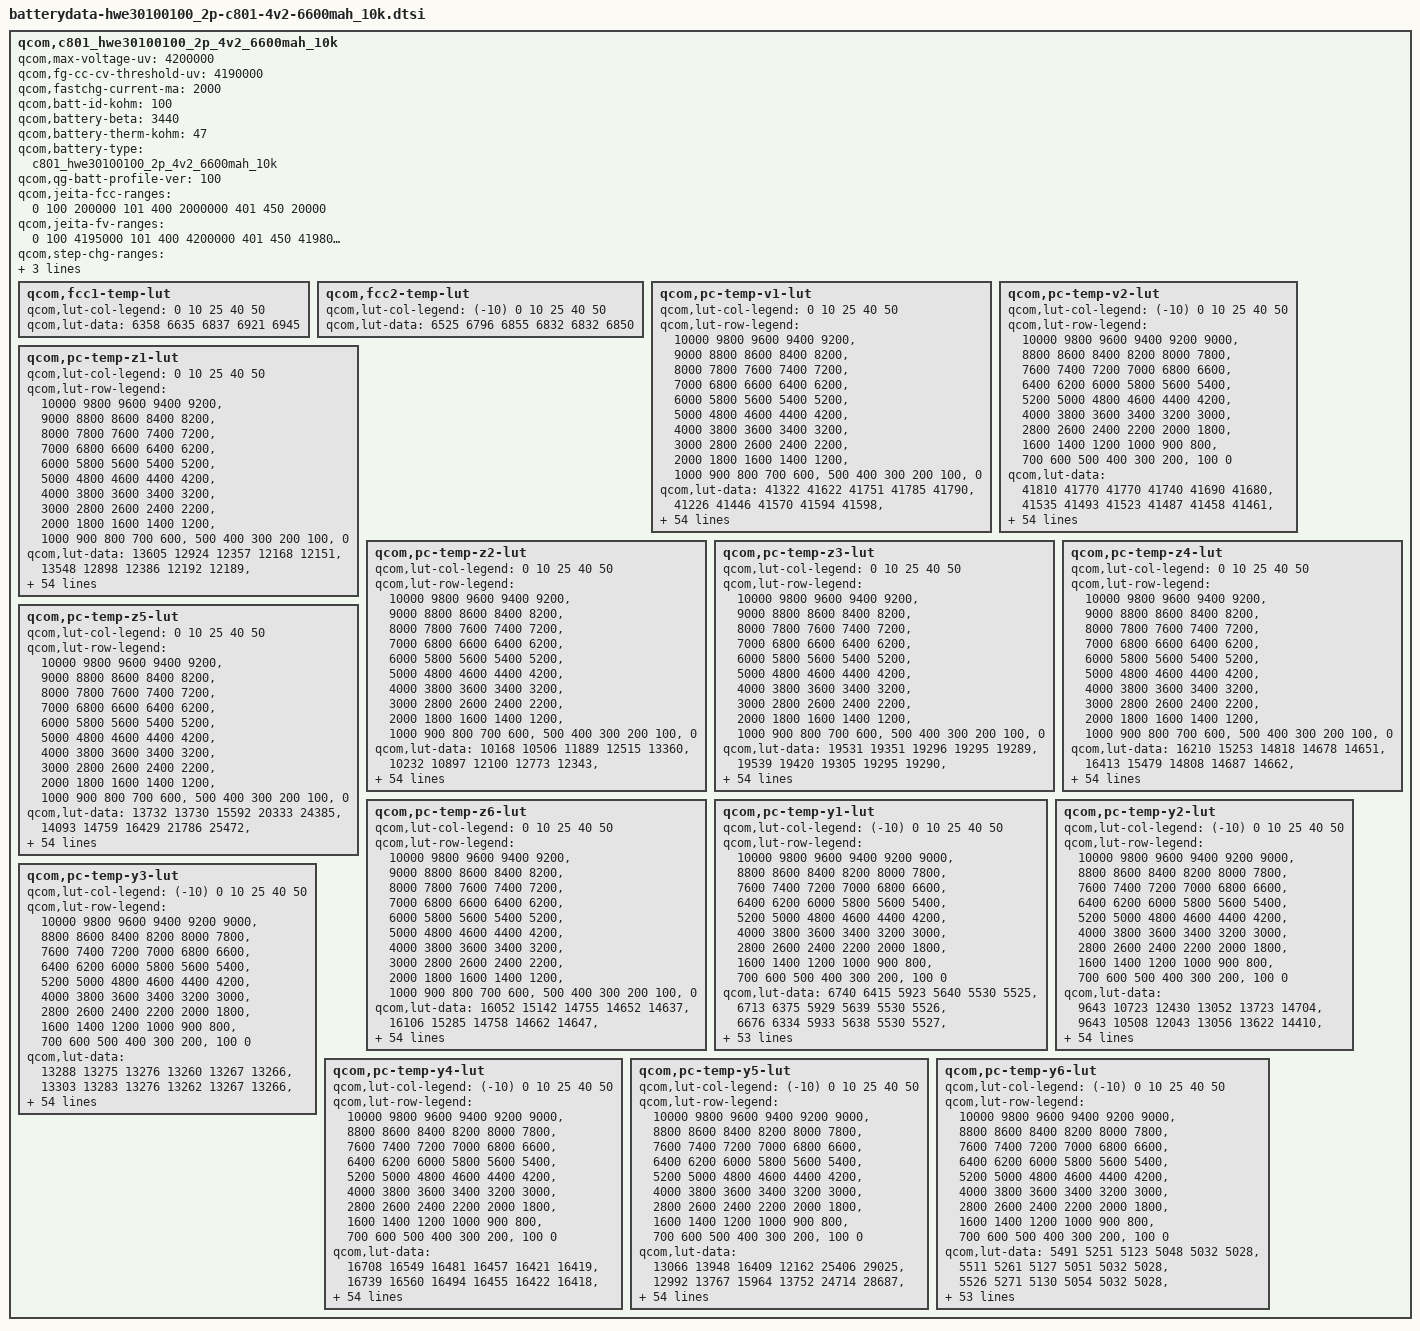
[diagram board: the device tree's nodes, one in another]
/* Copyright (c) 2018, The Linux Foundation. All rights reserved.
 *
 * This program is free software; you can redistribute it and/or modify
 * it under the terms of the GNU General Public License version 2 and
 * only version 2 as published by the Free Software Foundation.
 *
 * This program is distributed in the hope that it will be useful,
 * but WITHOUT ANY WARRANTY; without even the implied warranty of
 * MERCHANTABILITY or FITNESS FOR A PARTICULAR PURPOSE.  See the
 * GNU General Public License for more details.
 */

qcom,c801_hwe30100100_2p_4v2_6600mah_10k {
	/* 5174868_Quectel_SC60-R06_6600mAH_PMI632_averaged_MasterSlave_Apr15th2021*/
	qcom,max-voltage-uv = <4200000>;
	qcom,fg-cc-cv-threshold-uv = <4190000>;
	qcom,fastchg-current-ma = <2000>;
	/*qcom,batt-id-kohm = <10>;*/
	/*qcom,battery-beta = <3435>;*/
	/*qcom,battery-therm-kohm = <10>;*/
	qcom,batt-id-kohm = <100>; /* temporary for investigation */
	qcom,battery-beta = <3440>;
	qcom,battery-therm-kohm = <47>;
	qcom,battery-type = "c801_hwe30100100_2p_4v2_6600mah_10k";
	qcom,qg-batt-profile-ver = <100>;

	qcom,jeita-fcc-ranges = <0   100  200000
				101  400  2000000
				401  450  20000>;
	qcom,jeita-fv-ranges = <0   100  4195000
				101 400  4200000
				401 450  4198000>;
	qcom,step-chg-ranges = <3600000  4190000  2000000
				4191000  4195000  500000
				4196000  4200000  100000>;

	/* COOL = 5 DegC, WARM = 40 DegC */
	qcom,jeita-soft-thresholds = <0x5b70 0x3252>;
	/* COOL = 0 DegC, WARM = 45 DegC */
	/*qcom,jeita-soft-thresholds = <0x3730 0x0FB0>;*/
	/* COLD = 0 DegC, HOT = 45 DegC */
	qcom,jeita-hard-thresholds = <0x5fc9 0x2c99>;
	/* COLD = -10 DegC, HOT = 50 DegC */
	/*qcom,jeita-hard-thresholds = <0x448E 0x0D8F>;*/

	qcom,fcc1-temp-lut {
		qcom,lut-col-legend = <0 10 25 40 50>;
		qcom,lut-data = <6358 6635 6837 6921 6945>;
	};

	qcom,fcc2-temp-lut {
		qcom,lut-col-legend = <(-10) 0 10 25 40 50>;
		qcom,lut-data = <6525 6796 6855 6832 6832 6850>;
	};

	qcom,pc-temp-v1-lut {
		qcom,lut-col-legend = <0 10 25 40 50>;
		qcom,lut-row-legend = <10000 9800 9600 9400 9200>,
			<9000 8800 8600 8400 8200>,
			<8000 7800 7600 7400 7200>,
			<7000 6800 6600 6400 6200>,
			<6000 5800 5600 5400 5200>,
			<5000 4800 4600 4400 4200>,
			<4000 3800 3600 3400 3200>,
			<3000 2800 2600 2400 2200>,
			<2000 1800 1600 1400 1200>,
			<1000 900 800 700 600>,
			<500 400 300 200 100>,
			<0>;
		qcom,lut-data = <41322 41622 41751 41785 41790>,
			<41226 41446 41570 41594 41598>,
			<41016 41261 41378 41408 41408>,
			<40752 41081 41195 41227 41226>,
			<40483 40913 41019 41038 41040>,
			<40187 40736 40861 40864 40862>,
			<39956 40510 40711 40714 40697>,
			<39802 40239 40528 40562 40539>,
			<39680 40042 40287 40381 40379>,
			<39571 39919 40083 40190 40221>,
			<39478 39820 39960 40037 40070>,
			<39385 39723 39860 39913 39926>,
			<39274 39635 39748 39791 39789>,
			<39158 39542 39632 39659 39655>,
			<39044 39436 39515 39530 39528>,
			<38933 39331 39399 39409 39406>,
			<38829 39232 39287 39294 39290>,
			<38733 39138 39180 39183 39176>,
			<38646 39048 39078 39083 39071>,
			<38563 38960 38980 38968 38956>,
			<38476 38874 38892 38789 38792>,
			<38399 38791 38790 38592 38603>,
			<38348 38711 38628 38470 38472>,
			<38315 38638 38444 38387 38377>,
			<38278 38573 38329 38312 38295>,
			<38203 38510 38252 38239 38220>,
			<38108 38438 38192 38173 38153>,
			<38046 38363 38147 38114 38090>,
			<38012 38296 38108 38060 38033>,
			<37979 38237 38068 38012 37982>,
			<37924 38181 38029 37968 37936>,
			<37850 38123 37997 37931 37897>,
			<37785 38068 37970 37901 37867>,
			<37721 38025 37945 37873 37840>,
			<37675 37995 37923 37848 37807>,
			<37694 37967 37901 37823 37769>,
			<37809 37941 37873 37789 37725>,
			<37885 37915 37838 37744 37675>,
			<37882 37881 37791 37684 37614>,
			<37875 37831 37717 37608 37537>,
			<37855 37764 37618 37512 37440>,
			<37769 37660 37505 37400 37328>,
			<37659 37525 37374 37266 37195>,
			<37527 37382 37243 37132 37062>,
			<37392 37256 37130 37015 36948>,
			<37266 37157 37051 36944 36880>,
			<37211 37121 37021 36920 36854>,
			<37165 37089 36998 36900 36834>,
			<37122 37056 36972 36876 36808>,
			<37058 36988 36892 36774 36692>,
			<36899 36719 36604 36474 36383>,
			<36477 36287 36169 36033 35941>,
			<35929 35710 35601 35461 35370>,
			<35184 34930 34824 34684 34594>,
			<34022 33733 33637 33502 33417>,
			<30000 30000 30000 30000 30000>;
	};

	qcom,pc-temp-v2-lut {
		qcom,lut-col-legend = <(-10) 0 10 25 40 50>;
		qcom,lut-row-legend = <10000 9800 9600 9400 9200 9000>,
			<8800 8600 8400 8200 8000 7800>,
			<7600 7400 7200 7000 6800 6600>,
			<6400 6200 6000 5800 5600 5400>,
			<5200 5000 4800 4600 4400 4200>,
			<4000 3800 3600 3400 3200 3000>,
			<2800 2600 2400 2200 2000 1800>,
			<1600 1400 1200 1000 900 800>,
			<700 600 500 400 300 200>,
			<100 0>;
		qcom,lut-data = <41810 41770 41770 41740 41690 41680>,
			<41535 41493 41523 41487 41458 41461>,
			<41297 41259 41304 41262 41242 41253>,
			<41107 41087 41122 41073 41046 41058>,
			<40966 40960 40971 40914 40867 40874>,
			<40804 40800 40800 40744 40691 40698>,
			<40544 40535 40589 40547 40518 40529>,
			<40231 40242 40366 40346 40347 40365>,
			<39966 40006 40144 40152 40181 40205>,
			<39731 39794 39925 39963 40020 40050>,
			<39540 39633 39774 39821 39873 39900>,
			<39410 39517 39677 39720 39743 39758>,
			<39307 39410 39577 39622 39617 39621>,
			<39203 39290 39441 39504 39490 39489>,
			<39099 39166 39288 39377 39366 39363>,
			<38991 39040 39137 39255 39245 39242>,
			<38867 38909 38985 39138 39133 39131>,
			<38732 38783 38842 39006 39007 39007>,
			<38604 38666 38710 38834 38847 38857>,
			<38482 38556 38588 38656 38678 38700>,
			<38365 38448 38477 38514 38531 38548>,
			<38256 38344 38377 38392 38394 38400>,
			<38151 38247 38287 38291 38285 38286>,
			<38054 38159 38209 38208 38201 38202>,
			<37958 38077 38137 38137 38129 38129>,
			<37873 38005 38067 38070 38063 38060>,
			<37802 37939 38003 38011 38003 37998>,
			<37740 37877 37940 37955 37948 37940>,
			<37686 37817 37880 37903 37896 37888>,
			<37639 37762 37825 37855 37849 37841>,
			<37597 37720 37778 37809 37808 37799>,
			<37557 37683 37735 37767 37768 37759>,
			<37519 37638 37698 37728 37726 37717>,
			<37481 37581 37666 37693 37683 37674>,
			<37442 37523 37627 37654 37633 37617>,
			<37402 37461 37578 37607 37570 37530>,
			<37359 37399 37525 37556 37502 37440>,
			<37315 37346 37475 37502 37436 37366>,
			<37266 37299 37420 37443 37369 37297>,
			<37212 37256 37343 37375 37298 37229>,
			<37152 37218 37235 37290 37225 37162>,
			<37084 37181 37145 37201 37137 37075>,
			<37005 37145 37074 37104 37027 36963>,
			<36899 37097 37024 36962 36898 36834>,
			<36757 37019 36987 36891 36806 36747>,
			<36576 36922 36930 36858 36779 36719>,
			<36435 36851 36902 36835 36761 36700>,
			<36308 36744 36857 36814 36735 36674>,
			<36132 36606 36759 36761 36687 36620>,
			<35922 36410 36570 36613 36535 36453>,
			<35674 36073 36272 36263 36180 36096>,
			<35333 35721 35856 35772 35694 35610>,
			<34893 35232 35255 35140 35064 34973>,
			<34242 34541 34387 34276 34200 34109>,
			<33157 33411 33038 33058 33018 32927>,
			<30499 31323 30117 30069 30029 30027>;
	};

	qcom,pc-temp-z1-lut {
		qcom,lut-col-legend = <0 10 25 40 50>;
		qcom,lut-row-legend = <10000 9800 9600 9400 9200>,
			<9000 8800 8600 8400 8200>,
			<8000 7800 7600 7400 7200>,
			<7000 6800 6600 6400 6200>,
			<6000 5800 5600 5400 5200>,
			<5000 4800 4600 4400 4200>,
			<4000 3800 3600 3400 3200>,
			<3000 2800 2600 2400 2200>,
			<2000 1800 1600 1400 1200>,
			<1000 900 800 700 600>,
			<500 400 300 200 100>,
			<0>;
		qcom,lut-data = <13605 12924 12357 12168 12151>,
			<13548 12898 12386 12192 12189>,
			<13478 12928 12394 12205 12201>,
			<13423 12941 12405 12211 12206>,
			<13406 12939 12412 12215 12210>,
			<13398 12937 12411 12213 12210>,
			<13392 12940 12408 12181 12181>,
			<13388 12949 12398 12153 12148>,
			<13385 12952 12358 12157 12151>,
			<13377 12918 12331 12168 12168>,
			<13358 12882 12337 12188 12191>,
			<13337 12880 12352 12228 12229>,
			<13320 12883 12376 12249 12252>,
			<13303 12884 12419 12249 12251>,
			<13279 12877 12439 12250 12250>,
			<13240 12871 12440 12250 12251>,
			<13192 12875 12440 12251 12253>,
			<13138 12888 12442 12253 12255>,
			<13077 12899 12444 12254 12256>,
			<13026 12906 12446 12257 12258>,
			<12985 12914 12447 12259 12260>,
			<12952 12943 12448 12261 12262>,
			<12931 12993 12451 12264 12264>,
			<12917 13022 12454 12266 12265>,
			<12905 13036 12458 12268 12267>,
			<12891 13043 12463 12269 12268>,
			<12878 13043 12468 12271 12269>,
			<12875 13042 12472 12272 12270>,
			<12885 13042 12475 12273 12271>,
			<12900 13044 12477 12274 12271>,
			<12921 13048 12478 12274 12272>,
			<12952 13058 12480 12275 12273>,
			<12983 13074 12483 12276 12275>,
			<13009 13085 12486 12277 12276>,
			<13039 13094 12490 12278 12277>,
			<13086 13099 12494 12279 12278>,
			<13161 13095 12498 12281 12279>,
			<13249 13088 12503 12283 12280>,
			<13354 13087 12507 12285 12281>,
			<13467 13089 12508 12286 12282>,
			<13552 13093 12509 12287 12284>,
			<13622 13097 12512 12288 12284>,
			<13636 13103 12516 12291 12284>,
			<13576 13121 12518 12292 12285>,
			<13575 13119 12520 12293 12286>,
			<13636 13109 12521 12296 12289>,
			<13698 13121 12530 12298 12289>,
			<13719 13112 12526 12298 12289>,
			<13671 13135 12527 12300 12292>,
			<13681 13108 12539 12302 12294>,
			<13675 13143 12540 12307 12297>,
			<13685 13124 12553 12313 12303>,
			<13688 13160 12569 12322 12311>,
			<13728 13147 12583 12334 12321>,
			<13728 13147 12583 12334 12321>,
			<13728 13147 12583 12334 12321>;
	};

	qcom,pc-temp-z2-lut {
		qcom,lut-col-legend = <0 10 25 40 50>;
		qcom,lut-row-legend = <10000 9800 9600 9400 9200>,
			<9000 8800 8600 8400 8200>,
			<8000 7800 7600 7400 7200>,
			<7000 6800 6600 6400 6200>,
			<6000 5800 5600 5400 5200>,
			<5000 4800 4600 4400 4200>,
			<4000 3800 3600 3400 3200>,
			<3000 2800 2600 2400 2200>,
			<2000 1800 1600 1400 1200>,
			<1000 900 800 700 600>,
			<500 400 300 200 100>,
			<0>;
		qcom,lut-data = <10168 10506 11889 12515 13360>,
			<10232 10897 12100 12773 12343>,
			<10403 11124 12118 12938 12587>,
			<10551 11200 12131 12758 12862>,
			<10548 11207 12135 12726 12608>,
			<10484 11213 12113 12696 12468>,
			<10392 11228 12064 12659 12532>,
			<10170 11252 12052 12627 12610>,
			<9927 11272 12058 12599 12626>,
			<9888 11290 12063 12577 12633>,
			<9916 11301 12007 12592 12633>,
			<9940 11286 11923 12689 12615>,
			<9948 11242 11927 12753 12602>,
			<9954 11226 11998 12768 12638>,
			<9953 11249 12056 12775 12692>,
			<9932 11273 12085 12766 12688>,
			<9902 11245 12111 12733 12650>,
			<9875 11167 12149 12699 12634>,
			<9846 11133 12194 12661 12634>,
			<9834 11127 12243 12617 12634>,
			<9852 11124 12307 12565 12609>,
			<9887 11121 12344 12504 12536>,
			<9925 11120 12241 12422 12418>,
			<9975 11093 12067 12314 12192>,
			<10042 10800 12075 12209 12082>,
			<10126 10533 12261 12094 12096>,
			<10261 10731 12360 12019 12120>,
			<11450 11224 12309 12049 12141>,
			<21308 11455 12229 12126 12165>,
			<30541 11522 12168 12172 12200>,
			<26963 11575 12112 12192 12263>,
			<15450 11642 12096 12224 12344>,
			<10012 11708 12112 12371 12451>,
			<9893 11766 12143 12551 12572>,
			<9834 11825 12249 12616 12675>,
			<9827 11858 12432 12653 12773>,
			<9827 11669 12541 12656 12802>,
			<9826 11301 12605 12579 12773>,
			<9754 11216 12663 12514 12746>,
			<9628 11330 12738 12547 12779>,
			<9593 11513 12796 12612 12844>,
			<9593 11907 12780 12634 12833>,
			<9596 12283 12718 12641 12719>,
			<9616 12320 12704 12681 12665>,
			<9465 12112 12719 12766 12659>,
			<9446 11940 13048 12811 12903>,
			<9456 11975 13113 12844 12904>,
			<9434 11819 13335 13055 12871>,
			<9439 12044 13368 13152 12966>,
			<9465 11874 13234 13076 12729>,
			<9503 12633 12651 12582 12356>,
			<9887 12349 12378 12309 12380>,
			<9872 12034 12026 11982 12031>,
			<9973 11686 11621 11666 11830>,
			<9973 11686 11621 11666 11830>,
			<9973 11686 11621 11666 11830>;
	};

	qcom,pc-temp-z3-lut {
		qcom,lut-col-legend = <0 10 25 40 50>;
		qcom,lut-row-legend = <10000 9800 9600 9400 9200>,
			<9000 8800 8600 8400 8200>,
			<8000 7800 7600 7400 7200>,
			<7000 6800 6600 6400 6200>,
			<6000 5800 5600 5400 5200>,
			<5000 4800 4600 4400 4200>,
			<4000 3800 3600 3400 3200>,
			<3000 2800 2600 2400 2200>,
			<2000 1800 1600 1400 1200>,
			<1000 900 800 700 600>,
			<500 400 300 200 100>,
			<0>;
		qcom,lut-data = <19531 19351 19296 19295 19289>,
			<19539 19420 19305 19295 19290>,
			<19555 19467 19342 19298 19294>,
			<19567 19496 19354 19296 19295>,
			<19557 19516 19359 19304 19296>,
			<19516 19527 19358 19307 19297>,
			<19479 19525 19355 19305 19296>,
			<19451 19515 19351 19303 19295>,
			<19429 19503 19347 19303 19295>,
			<19423 19485 19341 19302 19294>,
			<19422 19467 19329 19301 19294>,
			<19420 19454 19317 19298 19295>,
			<19414 19444 19316 19296 19296>,
			<19406 19436 19317 19297 19294>,
			<19395 19431 19317 19299 19291>,
			<19382 19427 19313 19298 19289>,
			<19367 19420 19308 19296 19287>,
			<19346 19412 19307 19296 19287>,
			<19321 19409 19307 19296 19287>,
			<19301 19409 19307 19296 19288>,
			<19289 19409 19307 19302 19292>,
			<19280 19408 19307 19311 19299>,
			<19275 19407 19318 19313 19302>,
			<19272 19403 19338 19314 19303>,
			<19270 19374 19343 19314 19303>,
			<19268 19349 19345 19312 19302>,
			<19266 19361 19345 19309 19299>,
			<19263 19390 19342 19306 19298>,
			<19259 19399 19338 19303 19296>,
			<19256 19397 19334 19302 19296>,
			<19258 19396 19330 19303 19295>,
			<19266 19400 19326 19304 19295>,
			<19272 19407 19321 19304 19291>,
			<19277 19408 19318 19304 19287>,
			<19280 19401 19319 19303 19287>,
			<19280 19389 19323 19300 19290>,
			<19276 19367 19325 19299 19291>,
			<19273 19338 19327 19300 19290>,
			<19273 19324 19329 19300 19290>,
			<19274 19316 19330 19299 19290>,
			<19283 19313 19330 19296 19290>,
			<19342 19331 19332 19296 19290>,
			<19367 19358 19334 19298 19290>,
			<19362 19366 19333 19300 19291>,
			<19306 19346 19324 19301 19290>,
			<19290 19307 19300 19293 19285>,
			<19290 19295 19296 19289 19284>,
			<19289 19291 19291 19288 19284>,
			<19283 19287 19292 19286 19282>,
			<19287 19289 19297 19287 19286>,
			<19296 19347 19327 19298 19288>,
			<19372 19360 19322 19301 19289>,
			<19378 19382 19320 19304 19290>,
			<19412 19395 19319 19305 19292>,
			<19412 19395 19319 19305 19292>,
			<19412 19395 19319 19305 19292>;
	};

	qcom,pc-temp-z4-lut {
		qcom,lut-col-legend = <0 10 25 40 50>;
		qcom,lut-row-legend = <10000 9800 9600 9400 9200>,
			<9000 8800 8600 8400 8200>,
			<8000 7800 7600 7400 7200>,
			<7000 6800 6600 6400 6200>,
			<6000 5800 5600 5400 5200>,
			<5000 4800 4600 4400 4200>,
			<4000 3800 3600 3400 3200>,
			<3000 2800 2600 2400 2200>,
			<2000 1800 1600 1400 1200>,
			<1000 900 800 700 600>,
			<500 400 300 200 100>,
			<0>;
		qcom,lut-data = <16210 15253 14818 14678 14651>,
			<16413 15479 14808 14687 14662>,
			<16397 15470 14851 14682 14655>,
			<16365 15454 14830 14687 14659>,
			<16292 15387 14801 14680 14656>,
			<16140 15294 14780 14672 14652>,
			<16031 15216 14761 14665 14646>,
			<15988 15141 14743 14658 14640>,
			<15956 15078 14726 14652 14636>,
			<15912 15026 14714 14648 14632>,
			<15858 14983 14710 14644 14629>,
			<15811 14953 14706 14642 14624>,
			<15781 14929 14701 14639 14621>,
			<15757 14907 14693 14635 14621>,
			<15741 14883 14688 14630 14620>,
			<15727 14861 14686 14628 14619>,
			<15719 14844 14685 14627 14618>,
			<15719 14830 14681 14627 14618>,
			<15719 14814 14677 14626 14618>,
			<15719 14795 14673 14626 14618>,
			<15718 14778 14670 14663 14638>,
			<15715 14766 14668 14720 14675>,
			<15705 14757 14699 14723 14680>,
			<15672 14756 14750 14697 14663>,
			<15648 14774 14758 14676 14650>,
			<15666 14791 14750 14664 14643>,
			<15700 14776 14739 14655 14639>,
			<15714 14740 14719 14649 14635>,
			<15716 14728 14699 14645 14633>,
			<15719 14727 14688 14640 14630>,
			<15725 14726 14680 14635 14626>,
			<15737 14723 14674 14630 14623>,
			<15745 14720 14671 14626 14622>,
			<15750 14719 14667 14624 14622>,
			<15753 14719 14660 14624 14622>,
			<15732 14719 14652 14626 14623>,
			<15618 14731 14648 14628 14624>,
			<15483 14753 14647 14629 14623>,
			<15366 14759 14646 14630 14622>,
			<15242 14759 14649 14631 14622>,
			<15109 14758 14653 14632 14622>,
			<14952 14744 14658 14634 14622>,
			<14876 14721 14661 14637 14624>,
			<14854 14709 14660 14637 14627>,
			<14854 14716 14657 14634 14627>,
			<14850 14729 14657 14625 14619>,
			<14850 14731 14655 14624 14616>,
			<14845 14730 14654 14618 14609>,
			<14839 14727 14649 14616 14608>,
			<14832 14727 14651 14625 14612>,
			<14832 14709 14651 14625 14617>,
			<14822 14734 14668 14627 14619>,
			<14879 14743 14683 14629 14621>,
			<14907 14770 14703 14634 14623>,
			<14907 14770 14703 14634 14623>,
			<14907 14770 14703 14634 14623>;
	};

	qcom,pc-temp-z5-lut {
		qcom,lut-col-legend = <0 10 25 40 50>;
		qcom,lut-row-legend = <10000 9800 9600 9400 9200>,
			<9000 8800 8600 8400 8200>,
			<8000 7800 7600 7400 7200>,
			<7000 6800 6600 6400 6200>,
			<6000 5800 5600 5400 5200>,
			<5000 4800 4600 4400 4200>,
			<4000 3800 3600 3400 3200>,
			<3000 2800 2600 2400 2200>,
			<2000 1800 1600 1400 1200>,
			<1000 900 800 700 600>,
			<500 400 300 200 100>,
			<0>;
		qcom,lut-data = <13732 13730 15592 20333 24385>,
			<14093 14759 16429 21786 25472>,
			<15136 15859 20382 23131 28604>,
			<16541 16788 22004 22031 28370>,
			<18101 17589 22853 25992 30425>,
			<19956 18203 23137 27511 31944>,
			<20951 18541 23301 27353 32400>,
			<21181 18783 23330 27213 32732>,
			<21321 18846 23320 27469 33076>,
			<21456 18655 23297 27953 33412>,
			<21581 18399 21813 27732 34252>,
			<21681 18244 19617 26110 37116>,
			<21748 18119 19471 25257 39014>,
			<21802 18090 20165 27084 36121>,
			<21878 18244 20482 29204 31666>,
			<22016 18397 20078 29371 30686>,
			<22124 18372 19647 29378 30402>,
			<21982 18281 19788 29477 30421>,
			<21494 18287 20302 30456 32020>,
			<21106 18904 20773 32151 33480>,
			<20930 19769 21108 37087 33081>,
			<20777 20543 21689 43087 32010>,
			<20537 21307 33867 41406 31022>,
			<20180 21314 53518 31666 29954>,
			<19784 18798 55095 27318 29500>,
			<19380 16504 44869 27368 29712>,
			<18952 18688 35920 27417 30128>,
			<18528 24118 30582 27394 30654>,
			<18089 26806 26885 27339 31453>,
			<17691 27560 25512 27688 32743>,
			<17403 28386 24742 30425 35502>,
			<17172 31221 24276 33832 37191>,
			<16901 35301 23919 38024 34529>,
			<16576 36089 23740 41525 30592>,
			<16162 33039 25343 41362 32316>,
			<15478 28832 29119 39819 40265>,
			<14292 24009 32111 38929 43369>,
			<13200 18930 34730 38683 40438>,
			<12370 17245 36518 38370 37732>,
			<11706 16772 37330 36206 37622>,
			<11731 16582 37986 32948 37597>,
			<13228 19425 39350 32672 37398>,
			<14464 24255 41073 34004 36508>,
			<15172 27034 39314 34519 35301>,
			<13992 23994 32091 34959 33375>,
			<13614 17592 21386 30775 29143>,
			<13551 16237 20471 26708 28702>,
			<13457 15772 19341 27114 33168>,
			<13286 15614 19801 27159 31933>,
			<13435 15897 21422 25002 31063>,
			<14379 26923 30442 28596 28135>,
			<19945 23162 24011 27878 26245>,
			<17849 24084 20596 27480 25320>,
			<17921 21677 17975 24840 25276>,
			<17921 21677 17975 24840 25276>,
			<17921 21677 17975 24840 25276>;
	};

	qcom,pc-temp-z6-lut {
		qcom,lut-col-legend = <0 10 25 40 50>;
		qcom,lut-row-legend = <10000 9800 9600 9400 9200>,
			<9000 8800 8600 8400 8200>,
			<8000 7800 7600 7400 7200>,
			<7000 6800 6600 6400 6200>,
			<6000 5800 5600 5400 5200>,
			<5000 4800 4600 4400 4200>,
			<4000 3800 3600 3400 3200>,
			<3000 2800 2600 2400 2200>,
			<2000 1800 1600 1400 1200>,
			<1000 900 800 700 600>,
			<500 400 300 200 100>,
			<0>;
		qcom,lut-data = <16052 15142 14755 14652 14637>,
			<16106 15285 14758 14662 14647>,
			<16067 15307 14798 14663 14648>,
			<16004 15311 14795 14666 14651>,
			<15926 15291 14790 14667 14651>,
			<15821 15258 14782 14666 14650>,
			<15746 15225 14770 14656 14642>,
			<15707 15186 14757 14647 14633>,
			<15678 15150 14742 14645 14633>,
			<15651 15116 14730 14644 14633>,
			<15627 15087 14722 14645 14635>,
			<15604 15066 14717 14649 14640>,
			<15582 15048 14718 14651 14643>,
			<15561 15034 14722 14650 14642>,
			<15537 15022 14725 14649 14640>,
			<15509 15011 14722 14648 14639>,
			<15479 15004 14719 14647 14638>,
			<15449 14998 14717 14646 14638>,
			<15417 14991 14715 14647 14638>,
			<15390 14984 14714 14647 14639>,
			<15370 14980 14713 14667 14650>,
			<15352 14983 14713 14697 14671>,
			<15332 14990 14732 14699 14675>,
			<15309 14992 14765 14690 14669>,
			<15297 14986 14771 14681 14663>,
			<15303 14981 14769 14675 14659>,
			<15316 14982 14767 14670 14656>,
			<15321 14984 14759 14666 14654>,
			<15323 14984 14748 14662 14652>,
			<15325 14984 14742 14660 14651>,
			<15333 14983 14737 14658 14649>,
			<15355 14985 14732 14656 14647>,
			<15377 14990 14728 14655 14645>,
			<15403 14991 14726 14654 14643>,
			<15424 14988 14724 14653 14643>,
			<15424 14985 14722 14653 14645>,
			<15409 14982 14722 14653 14646>,
			<15399 14979 14723 14654 14645>,
			<15417 14976 14724 14655 14645>,
			<15453 14972 14726 14654 14645>,
			<15472 14970 14729 14654 14645>,
			<15482 14974 14733 14655 14645>,
			<15484 14978 14736 14658 14647>,
			<15470 14978 14735 14659 14648>,
			<15429 14968 14729 14658 14648>,
			<15420 14955 14718 14651 14642>,
			<15441 14947 14716 14648 14640>,
			<15439 14948 14712 14645 14638>,
			<15433 14947 14712 14644 14636>,
			<15430 14949 14716 14648 14640>,
			<15433 14973 14732 14656 14645>,
			<15471 14995 14741 14659 14648>,
			<15499 15017 14750 14664 14651>,
			<15538 15046 14765 14670 14656>,
			<15538 15046 14765 14670 14656>,
			<15538 15046 14765 14670 14656>;
	};

	qcom,pc-temp-y1-lut {
		qcom,lut-col-legend = <(-10) 0 10 25 40 50>;
		qcom,lut-row-legend = <10000 9800 9600 9400 9200 9000>,
			<8800 8600 8400 8200 8000 7800>,
			<7600 7400 7200 7000 6800 6600>,
			<6400 6200 6000 5800 5600 5400>,
			<5200 5000 4800 4600 4400 4200>,
			<4000 3800 3600 3400 3200 3000>,
			<2800 2600 2400 2200 2000 1800>,
			<1600 1400 1200 1000 900 800>,
			<700 600 500 400 300 200>,
			<100 0>;
		qcom,lut-data = <6740 6415 5923 5640 5530 5525>,
			<6713 6375 5929 5639 5530 5526>,
			<6676 6334 5933 5638 5530 5527>,
			<6638 6297 5934 5636 5530 5527>,
			<6607 6271 5935 5635 5530 5528>,
			<6588 6263 5935 5635 5530 5529>,
			<6581 6273 5933 5635 5530 5531>,
			<6577 6284 5931 5635 5531 5532>,
			<6578 6280 5931 5637 5533 5531>,
			<6591 6264 5933 5641 5536 5530>,
			<6601 6259 5936 5643 5536 5530>,
			<6602 6264 5939 5642 5537 5534>,
			<6603 6268 5941 5640 5537 5537>,
			<6607 6267 5940 5640 5537 5537>,
			<6631 6264 5938 5639 5538 5535>,
			<6651 6264 5939 5639 5539 5536>,
			<6643 6270 5946 5641 5540 5537>,
			<6622 6273 5949 5642 5540 5538>,
			<6615 6273 5944 5644 5541 5539>,
			<6614 6272 5939 5646 5541 5539>,
			<6614 6272 5942 5646 5542 5540>,
			<6623 6273 5952 5647 5542 5541>,
			<6647 6274 5954 5647 5543 5542>,
			<6654 6279 5951 5650 5544 5542>,
			<6636 6285 5948 5652 5545 5542>,
			<6616 6284 5951 5652 5545 5543>,
			<6618 6282 5956 5652 5545 5543>,
			<6626 6280 5963 5653 5545 5543>,
			<6629 6277 5972 5656 5548 5544>,
			<6629 6276 5976 5659 5550 5544>,
			<6628 6278 5966 5661 5552 5546>,
			<6626 6283 5954 5662 5554 5548>,
			<6621 6286 5954 5662 5554 5548>,
			<6619 6288 5954 5662 5554 5548>,
			<6635 6288 5955 5662 5554 5548>,
			<6655 6286 5953 5663 5555 5549>,
			<6657 6282 5952 5665 5555 5550>,
			<6656 6281 5953 5666 5555 5552>,
			<6654 6280 5955 5668 5556 5553>,
			<6638 6280 5957 5669 5556 5553>,
			<6616 6285 5959 5670 5557 5552>,
			<6630 6294 5961 5671 5557 5552>,
			<6695 6307 5967 5672 5556 5552>,
			<6692 6299 5976 5672 5557 5554>,
			<6650 6335 5972 5674 5560 5555>,
			<6663 6326 5967 5676 5560 5555>,
			<6671 6312 5970 5679 5561 5556>,
			<6667 6323 5979 5680 5561 5556>,
			<6660 6321 5992 5683 5561 5557>,
			<6665 6351 5992 5685 5563 5558>,
			<6751 6335 5996 5693 5565 5559>,
			<6734 6340 5998 5695 5569 5563>,
			<6767 6348 6025 5706 5575 5570>,
			<6853 6376 6029 5718 5585 5575>,
			<6853 6376 6029 5718 5585 5575>,
			<6853 6376 6029 5718 5585 5575>;
	};

	qcom,pc-temp-y2-lut {
		qcom,lut-col-legend = <(-10) 0 10 25 40 50>;
		qcom,lut-row-legend = <10000 9800 9600 9400 9200 9000>,
			<8800 8600 8400 8200 8000 7800>,
			<7600 7400 7200 7000 6800 6600>,
			<6400 6200 6000 5800 5600 5400>,
			<5200 5000 4800 4600 4400 4200>,
			<4000 3800 3600 3400 3200 3000>,
			<2800 2600 2400 2200 2000 1800>,
			<1600 1400 1200 1000 900 800>,
			<700 600 500 400 300 200>,
			<100 0>;
		qcom,lut-data = <9643 10723 12430 13052 13723 14704>,
			<9643 10508 12043 13056 13622 14410>,
			<9863 10446 11707 13005 13518 14038>,
			<10333 10501 11445 12908 13412 13664>,
			<10736 10638 11282 12775 13303 13365>,
			<11035 10825 11240 12612 13191 13213>,
			<11264 11166 11317 12342 13067 13151>,
			<11432 11507 11451 12132 12953 13110>,
			<11463 11649 11621 12150 12861 13075>,
			<11442 11734 11837 12226 12784 13047>,
			<11401 11809 11981 12254 12770 13010>,
			<11078 11877 12069 12256 12825 12962>,
			<10506 11944 12148 12259 12868 12903>,
			<10416 12031 12234 12279 12766 12816>,
			<11075 12121 12319 12324 12590 12722>,
			<11642 12171 12404 12409 12572 12670>,
			<11207 12196 12487 12599 12652 12633>,
			<10202 12224 12584 12779 12720 12623>,
			<9883 12285 12734 12902 12744 12717>,
			<10066 12347 12864 13017 12770 12881>,
			<10239 12139 12903 13166 12893 13059>,
			<10245 11277 12922 13336 13175 13271>,
			<10235 10849 12961 13390 13338 13428>,
			<10220 10840 13063 13391 13409 13556>,
			<10183 10836 13147 13392 13443 13621>,
			<10142 11224 13175 13418 13438 13602>,
			<10121 12282 13193 13475 13426 13557>,
			<10107 12649 13208 13504 13444 13521>,
			<10091 12630 13222 13520 13571 13485>,
			<10071 12604 13227 13526 13654 13470>,
			<10051 12579 13218 13516 13618 13491>,
			<10032 12553 13202 13492 13551 13533>,
			<10014 12536 13183 13456 13487 13598>,
			<9990 12526 13158 13391 13416 13692>,
			<9951 12513 13139 13322 13395 13713>,
			<9904 12491 13130 13238 13527 13589>,
			<9861 12457 13116 13179 13661 13483>,
			<9819 12385 13054 13192 13619 13484>,
			<9784 12234 12965 13230 13493 13495>,
			<9755 12103 12954 13234 13430 13533>,
			<9731 12019 12978 13187 13404 13647>,
			<9714 11941 12967 13208 13400 13591>,
			<9701 11857 12896 13331 13408 13350>,
			<9689 11835 12747 13297 13421 13280>,
			<9679 11938 12700 13789 13475 13328>,
			<9675 11820 12480 13154 13367 13315>,
			<9683 11728 12433 13028 13440 13200>,
			<9678 11560 12419 12933 13329 13010>,
			<9673 11406 12382 12819 13152 12971>,
			<9670 11187 12212 12761 12973 12990>,
			<9666 9839 11937 12555 12828 12770>,
			<9664 9684 11676 12270 12685 12397>,
			<9661 9667 11233 11989 12379 12353>,
			<9660 9662 10656 11642 11796 11953>,
			<9660 9662 10656 11642 11796 11953>,
			<9660 9662 10656 11642 11796 11953>;
	};

	qcom,pc-temp-y3-lut {
		qcom,lut-col-legend = <(-10) 0 10 25 40 50>;
		qcom,lut-row-legend = <10000 9800 9600 9400 9200 9000>,
			<8800 8600 8400 8200 8000 7800>,
			<7600 7400 7200 7000 6800 6600>,
			<6400 6200 6000 5800 5600 5400>,
			<5200 5000 4800 4600 4400 4200>,
			<4000 3800 3600 3400 3200 3000>,
			<2800 2600 2400 2200 2000 1800>,
			<1600 1400 1200 1000 900 800>,
			<700 600 500 400 300 200>,
			<100 0>;
		qcom,lut-data = <13288 13275 13276 13260 13267 13266>,
			<13303 13283 13276 13262 13267 13266>,
			<13321 13291 13277 13266 13267 13266>,
			<13339 13298 13278 13269 13267 13266>,
			<13353 13304 13279 13272 13267 13266>,
			<13360 13309 13281 13273 13267 13266>,
			<13358 13315 13283 13273 13268 13266>,
			<13355 13318 13285 13274 13268 13267>,
			<13350 13318 13288 13274 13268 13267>,
			<13337 13317 13292 13274 13268 13267>,
			<13325 13316 13297 13275 13268 13267>,
			<13319 13314 13303 13277 13268 13267>,
			<13315 13312 13307 13280 13268 13267>,
			<13315 13311 13304 13282 13269 13267>,
			<13326 13311 13299 13284 13271 13267>,
			<13335 13309 13296 13285 13272 13267>,
			<13331 13306 13295 13286 13274 13269>,
			<13319 13303 13293 13287 13274 13269>,
			<13314 13302 13289 13284 13273 13269>,
			<13313 13301 13286 13279 13272 13269>,
			<13312 13298 13281 13275 13270 13268>,
			<13312 13290 13276 13272 13267 13266>,
			<13312 13285 13275 13271 13266 13266>,
			<13312 13285 13278 13272 13266 13266>,
			<13311 13284 13282 13272 13266 13265>,
			<13309 13287 13283 13272 13267 13266>,
			<13309 13297 13284 13273 13268 13266>,
			<13310 13300 13284 13273 13268 13266>,
			<13312 13299 13284 13273 13268 13266>,
			<13314 13298 13283 13273 13267 13266>,
			<13317 13300 13284 13273 13267 13266>,
			<13320 13305 13284 13274 13267 13265>,
			<13324 13306 13286 13274 13267 13265>,
			<13329 13305 13288 13273 13268 13266>,
			<13334 13304 13289 13273 13268 13266>,
			<13342 13299 13289 13273 13268 13266>,
			<13350 13294 13289 13274 13268 13266>,
			<13362 13293 13290 13273 13268 13266>,
			<13377 13295 13292 13273 13268 13266>,
			<13397 13297 13292 13273 13268 13266>,
			<13422 13307 13290 13273 13267 13265>,
			<13451 13321 13287 13274 13267 13266>,
			<13484 13339 13283 13277 13267 13266>,
			<13523 13350 13285 13272 13268 13265>,
			<13564 13337 13293 13267 13267 13266>,
			<13590 13348 13299 13273 13268 13266>,
			<13494 13354 13306 13273 13268 13267>,
			<13530 13360 13312 13280 13270 13267>,
			<13569 13370 13315 13282 13271 13268>,
			<13633 13383 13316 13284 13270 13268>,
			<13713 13424 13320 13282 13268 13268>,
			<13830 13514 13329 13283 13272 13269>,
			<14003 13685 13343 13291 13274 13269>,
			<14229 14045 13376 13302 13275 13271>,
			<14229 14045 13376 13302 13275 13271>,
			<14229 14045 13376 13302 13275 13271>;
	};

	qcom,pc-temp-y4-lut {
		qcom,lut-col-legend = <(-10) 0 10 25 40 50>;
		qcom,lut-row-legend = <10000 9800 9600 9400 9200 9000>,
			<8800 8600 8400 8200 8000 7800>,
			<7600 7400 7200 7000 6800 6600>,
			<6400 6200 6000 5800 5600 5400>,
			<5200 5000 4800 4600 4400 4200>,
			<4000 3800 3600 3400 3200 3000>,
			<2800 2600 2400 2200 2000 1800>,
			<1600 1400 1200 1000 900 800>,
			<700 600 500 400 300 200>,
			<100 0>;
		qcom,lut-data = <16708 16549 16481 16457 16421 16419>,
			<16739 16560 16494 16455 16422 16418>,
			<16762 16585 16506 16454 16423 16417>,
			<16778 16614 16517 16454 16425 16417>,
			<16787 16637 16528 16455 16426 16418>,
			<16790 16645 16539 16456 16427 16418>,
			<16785 16645 16551 16458 16428 16419>,
			<16774 16645 16559 16461 16428 16421>,
			<16762 16638 16560 16464 16430 16422>,
			<16743 16622 16559 16468 16433 16423>,
			<16731 16617 16560 16472 16436 16424>,
			<16746 16619 16568 16476 16439 16425>,
			<16776 16621 16575 16482 16442 16428>,
			<16782 16619 16572 16489 16445 16431>,
			<16763 16613 16566 16499 16449 16434>,
			<16747 16609 16557 16513 16457 16440>,
			<16758 16605 16539 16532 16473 16449>,
			<16782 16602 16525 16541 16482 16454>,
			<16789 16598 16515 16517 16477 16456>,
			<16771 16595 16509 16483 16467 16457>,
			<16750 16598 16511 16465 16454 16449>,
			<16738 16612 16515 16452 16437 16429>,
			<16729 16618 16516 16447 16429 16422>,
			<16726 16618 16510 16445 16428 16421>,
			<16726 16618 16506 16444 16427 16420>,
			<16727 16610 16504 16444 16426 16421>,
			<16731 16591 16504 16446 16425 16421>,
			<16744 16584 16504 16448 16426 16421>,
			<16758 16586 16507 16450 16428 16423>,
			<16776 16588 16509 16453 16432 16425>,
			<16796 16587 16512 16455 16436 16428>,
			<16818 16586 16514 16456 16439 16431>,
			<16843 16582 16518 16458 16440 16434>,
			<16870 16574 16522 16461 16441 16436>,
			<16903 16568 16525 16462 16440 16436>,
			<16939 16571 16527 16460 16434 16427>,
			<16979 16576 16529 16457 16427 16419>,
			<17022 16587 16539 16457 16426 16419>,
			<17069 16611 16553 16458 16426 16419>,
			<17122 16641 16549 16459 16426 16421>,
			<17177 16680 16520 16461 16432 16425>,
			<17232 16728 16511 16464 16433 16425>,
			<17287 16788 16510 16467 16433 16424>,
			<17319 16823 16517 16452 16430 16424>,
			<17333 16747 16525 16451 16421 16416>,
			<17257 16793 16568 16453 16427 16421>,
			<17012 16818 16604 16463 16433 16426>,
			<17033 16838 16649 16477 16438 16433>,
			<17045 16862 16687 16505 16448 16441>,
			<17074 16871 16693 16517 16448 16433>,
			<17111 16889 16685 16497 16439 16427>,
			<17251 16927 16678 16492 16440 16431>,
			<17561 16959 16678 16509 16450 16438>,
			<18147 17238 16712 16560 16483 16468>,
			<18147 17238 16712 16560 16483 16468>,
			<18147 17238 16712 16560 16483 16468>;
	};

	qcom,pc-temp-y5-lut {
		qcom,lut-col-legend = <(-10) 0 10 25 40 50>;
		qcom,lut-row-legend = <10000 9800 9600 9400 9200 9000>,
			<8800 8600 8400 8200 8000 7800>,
			<7600 7400 7200 7000 6800 6600>,
			<6400 6200 6000 5800 5600 5400>,
			<5200 5000 4800 4600 4400 4200>,
			<4000 3800 3600 3400 3200 3000>,
			<2800 2600 2400 2200 2000 1800>,
			<1600 1400 1200 1000 900 800>,
			<700 600 500 400 300 200>,
			<100 0>;
		qcom,lut-data = <13066 13948 16409 12162 25406 29025>,
			<12992 13767 15964 13752 24714 28687>,
			<13134 13686 15265 15426 24056 28293>,
			<13455 13691 14529 16914 23446 27910>,
			<13917 13768 13972 17940 22898 27600>,
			<14484 13918 13803 18237 22426 27427>,
			<15387 14760 13840 17937 22073 27366>,
			<16351 15885 13926 17467 21696 27298>,
			<16442 16617 14287 17005 21047 26600>,
			<15491 17218 15230 16525 20134 24923>,
			<14504 17368 16568 16445 19309 23714>,
			<13983 17191 19075 16962 18457 22940>,
			<13594 17036 20620 17650 17989 22223>,
			<13663 17264 20446 18195 18701 21293>,
			<15085 17723 20167 18806 20052 20491>,
			<16306 17768 20313 19878 20619 20461>,
			<15701 17345 21110 21808 20820 20948>,
			<14270 17065 21478 23137 21166 21699>,
			<13802 17077 20567 23730 23137 23561>,
			<13911 17095 19077 24066 25269 25443>,
			<14013 16725 17485 23333 24892 25928>,
			<14007 15238 15746 21068 23157 26144>,
			<13966 14511 15410 20254 22433 26526>,
			<13884 14513 16755 20765 22361 27345>,
			<13522 14518 18242 21437 22331 28098>,
			<13105 15317 19189 21965 23880 28478>,
			<12906 17476 19894 22434 27001 28764>,
			<12770 18225 19944 22607 27498 29087>,
			<12683 18182 19706 22656 25937 29462>,
			<12618 18145 19584 22728 24928 29607>,
			<12580 19081 19823 23143 24942 28367>,
			<12587 20907 20308 23641 24982 26880>,
			<12628 21293 21261 23622 25366 27009>,
			<12676 20941 22781 23332 26748 28068>,
			<12723 20346 23243 23225 27934 29761>,
			<12783 18615 23071 23741 28845 34033>,
			<12875 16340 22930 24266 29407 37222>,
			<13022 15254 23522 24043 29431 36471>,
			<13208 14562 24583 23398 29427 34344>,
			<13450 14350 24719 23000 29013 31647>,
			<13758 14831 24185 22772 25854 27965>,
			<14145 15596 22035 24033 24287 28682>,
			<14646 16643 18740 28648 23881 31449>,
			<15114 17851 18370 22290 26999 27702>,
			<15619 20519 20968 16883 26373 33561>,
			<16602 21500 20161 20923 24947 27933>,
			<16837 22034 21076 19962 23612 26082>,
			<17126 22107 22292 23576 24383 25468>,
			<16882 22637 22968 22961 25623 25096>,
			<16731 22551 23147 23280 22355 27255>,
			<16768 17967 22835 21355 20950 29256>,
			<15311 17077 22549 21267 26052 31046>,
			<13832 15691 20860 24570 29483 28065>,
			<12164 13175 18229 25559 26815 27892>,
			<12164 13175 18229 25559 26815 27892>,
			<12164 13175 18229 25559 26815 27892>;
	};

	qcom,pc-temp-y6-lut {
		qcom,lut-col-legend = <(-10) 0 10 25 40 50>;
		qcom,lut-row-legend = <10000 9800 9600 9400 9200 9000>,
			<8800 8600 8400 8200 8000 7800>,
			<7600 7400 7200 7000 6800 6600>,
			<6400 6200 6000 5800 5600 5400>,
			<5200 5000 4800 4600 4400 4200>,
			<4000 3800 3600 3400 3200 3000>,
			<2800 2600 2400 2200 2000 1800>,
			<1600 1400 1200 1000 900 800>,
			<700 600 500 400 300 200>,
			<100 0>;
		qcom,lut-data = <5491 5251 5123 5048 5032 5028>,
			<5511 5261 5127 5051 5032 5028>,
			<5526 5271 5130 5054 5032 5028>,
			<5537 5282 5134 5056 5032 5029>,
			<5544 5290 5138 5058 5033 5029>,
			<5546 5296 5143 5060 5033 5030>,
			<5543 5299 5147 5061 5034 5030>,
			<5536 5301 5152 5062 5035 5031>,
			<5528 5299 5155 5063 5036 5031>,
			<5518 5293 5158 5065 5036 5031>,
			<5511 5291 5162 5067 5037 5032>,
			<5514 5290 5169 5070 5038 5033>,
			<5519 5289 5173 5073 5039 5034>,
			<5525 5288 5170 5077 5041 5035>,
			<5533 5286 5164 5081 5043 5036>,
			<5538 5284 5158 5086 5047 5038>,
			<5537 5281 5152 5092 5053 5042>,
			<5536 5280 5146 5095 5055 5044>,
			<5536 5279 5141 5086 5053 5044>,
			<5536 5279 5137 5072 5049 5044>,
			<5536 5279 5135 5065 5044 5041>,
			<5537 5278 5132 5059 5037 5034>,
			<5539 5277 5132 5057 5035 5031>,
			<5542 5278 5133 5057 5034 5031>,
			<5545 5279 5135 5057 5034 5031>,
			<5549 5282 5136 5057 5034 5031>,
			<5554 5285 5136 5058 5035 5031>,
			<5562 5287 5137 5058 5035 5031>,
			<5571 5288 5138 5059 5036 5032>,
			<5582 5289 5139 5060 5036 5033>,
			<5595 5293 5140 5061 5037 5034>,
			<5608 5297 5141 5062 5038 5035>,
			<5623 5298 5144 5063 5039 5035>,
			<5639 5297 5147 5063 5040 5036>,
			<5659 5296 5149 5064 5040 5036>,
			<5682 5297 5150 5063 5038 5034>,
			<5707 5298 5152 5063 5036 5032>,
			<5735 5302 5156 5063 5036 5032>,
			<5768 5313 5161 5063 5036 5032>,
			<5806 5328 5160 5064 5036 5032>,
			<5850 5351 5152 5065 5037 5033>,
			<5900 5381 5148 5066 5037 5033>,
			<5958 5419 5147 5070 5037 5033>,
			<6017 5448 5152 5062 5037 5033>,
			<6070 5418 5161 5059 5034 5031>,
			<6092 5454 5179 5063 5036 5033>,
			<5951 5478 5195 5067 5039 5035>,
			<5998 5504 5215 5076 5041 5037>,
			<6042 5543 5230 5086 5045 5041>,
			<6112 5592 5237 5091 5045 5038>,
			<6196 5654 5243 5085 5041 5037>,
			<6355 5780 5259 5086 5044 5039>,
			<6622 5960 5292 5101 5050 5042>,
			<7021 6351 5384 5129 5062 5053>,
			<7021 6351 5384 5129 5062 5053>,
			<7021 6351 5384 5129 5062 5053>;
	};
};
